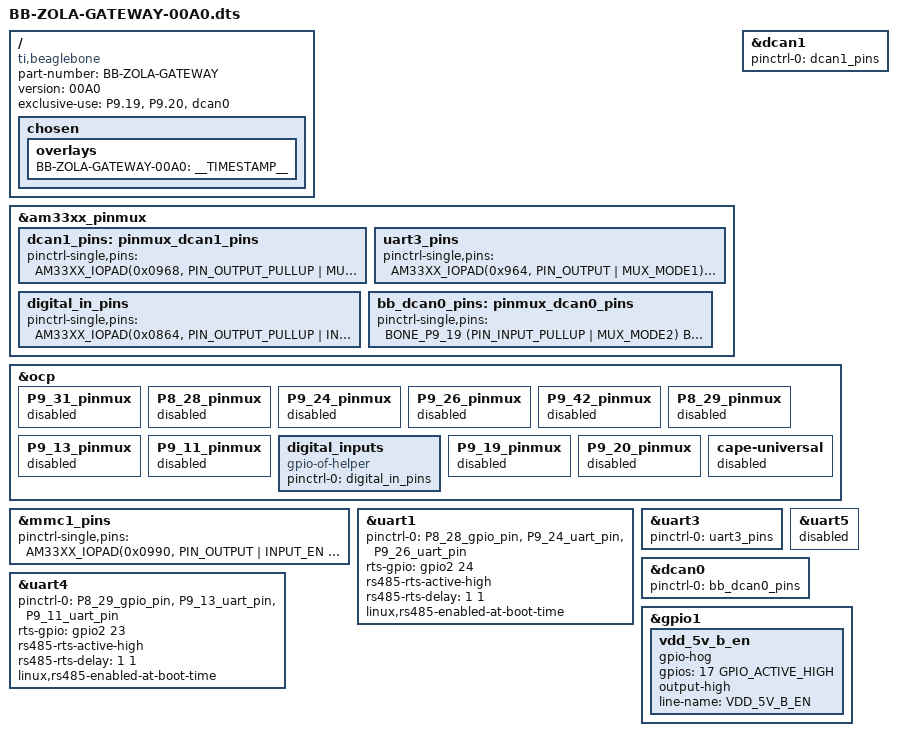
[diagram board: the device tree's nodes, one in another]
/*
 * Copyright (c) 2021 Seeed Studio
 *                    Peter Yang <turmary@126.com>
 *
 * Virtual cape for Zola Gateway
 *
 * This program is free software; you can redistribute it and/or modify
 * it under the terms of the GNU General Public License version 2 as
 * published by the Free Software Foundation.
 */
/dts-v1/;
/plugin/;

#include <dt-bindings/gpio/gpio.h>
#include <dt-bindings/board/am335x-bbw-bbb-base.h>
#include <dt-bindings/pinctrl/am33xx.h>

/ {
	compatible = "ti,beaglebone", "ti,beaglebone-black", "ti,beaglebone-green";

	/* identification */
	part-number = "BB-ZOLA-GATEWAY";
	version = "00A0";

	/* state the resources this cape uses */
	exclusive-use =
		/* the pin header uses */
		"P9.19",	/* dcan0_rx */
		"P9.20",	/* dcan0_tx */
		/* the hardware ip uses */
		"dcan0";

	/*
	 * Helper to show loaded overlays under: /proc/device-tree/chosen/overlays/
	 */
	fragment@1000 {
		target-path="/";
		__overlay__ {

			chosen {
				overlays {
					BB-ZOLA-GATEWAY-00A0 =__TIMESTAMP__;
				};
			};
		};
	};

	/*
	 * Free up the pins used by the cape from the pinmux helpers.
	 */
	fragment@1001 {
		target = <&ocp>;
		__overlay__ {
			P9_19_pinmux { status = "disabled"; };	/* P9_19: i2c2_scl.d_can0_rx */
			P9_20_pinmux { status = "disabled"; };	/* P9_20: i2c2_sda.d_can0_tx */

			/*
			 * Free up the gpios used by the cape-universal gpio helpers.
			 */
			cape-universal { status = "disabled"; };
		};
	};

	fragment@1002 {
		target = <&am33xx_pinmux>;
		__overlay__ {
			bb_dcan0_pins: pinmux_dcan0_pins {
				pinctrl-single,pins = <
					BONE_P9_19 (PIN_INPUT_PULLUP | MUX_MODE2)	/* P9_19: i2c2_scl.d_can0_rx */
					BONE_P9_20 (PIN_OUTPUT_PULLUP | MUX_MODE2)	/* P9_20: i2c2_sda.d_can0_tx */
				>;
			};
		};
	};

	fragment@1003 {
		target = <&dcan0>;
		__overlay__ {
			status = "okay";
			pinctrl-names = "default";
			pinctrl-0 = <&bb_dcan0_pins>;
		};
	};

	fragment@1010 {
		target = <&gpio1>;
		__overlay__ {
			vdd_5v_b_en {
				gpio-hog;
				gpios = <17 GPIO_ACTIVE_HIGH>;
				output-high;
				line-name = "VDD_5V_B_EN";
			};
		};
	};
};

/* DCAN1 */
&am33xx_pinmux {
	dcan1_pins: pinmux_dcan1_pins {
		pinctrl-single,pins = <
			AM33XX_IOPAD(0x0968, PIN_OUTPUT_PULLUP | MUX_MODE2)  /* uart0_ctsn.dcan1_tx */
			AM33XX_IOPAD(0x096c, PIN_INPUT_PULLUP | MUX_MODE2)   /* uart0_rtsn.dcan1_rx */
		>;
	};
};
&dcan1 {
	status = "okay";
	pinctrl-names = "default";
	pinctrl-0 = <&dcan1_pins>;
};

/* MMC1(SDCard) CD gpio0_6 -> gpio3_14 */
&ocp {
	P9_31_pinmux { status = "disabled"; };	/* P9_31: mcasp0_aclkx.gpio3_14 */
};
&mmc1_pins {
	pinctrl-single,pins = <
		AM33XX_IOPAD(0x0990, PIN_OUTPUT | INPUT_EN | MUX_MODE7)  /* mcasp0_aclkx.gpio3_14 */
		AM33XX_PADCONF(AM335X_PIN_MMC0_DAT0, PIN_INPUT_PULLUP, MUX_MODE0)
		AM33XX_PADCONF(AM335X_PIN_MMC0_DAT1, PIN_INPUT_PULLUP, MUX_MODE0)
		AM33XX_PADCONF(AM335X_PIN_MMC0_DAT2, PIN_INPUT_PULLUP, MUX_MODE0)
		AM33XX_PADCONF(AM335X_PIN_MMC0_DAT3, PIN_INPUT_PULLUP, MUX_MODE0)
		AM33XX_PADCONF(AM335X_PIN_MMC0_CMD, PIN_INPUT_PULLUP, MUX_MODE0)
		AM33XX_PADCONF(AM335X_PIN_MMC0_CLK, PIN_INPUT_PULLUP, MUX_MODE0)
	>;
};

/* RS485_1(UART1) on J6 */
&ocp {
	P8_28_pinmux { status = "disabled"; };	/* P8_28: lcd_pclk.gpio2_24 */
	P9_24_pinmux { status = "disabled"; };	/* P9_24: uart1_txd.uart1_txd */
	P9_26_pinmux { status = "disabled"; };	/* P9_26: uart1_rxd.uart1_rxd */
};
&uart1 {
	status = "okay";
	pinctrl-names = "default";
	pinctrl-0 = <&P8_28_gpio_pin &P9_24_uart_pin &P9_26_uart_pin>;
	rts-gpio = <&gpio2 24 GPIO_ACTIVE_HIGH>;
	rs485-rts-active-high;
	/* rs485-rx-during-tx; */
	rs485-rts-delay = <1 1>;
	linux,rs485-enabled-at-boot-time;
};

/* UART3 */
&ocp {
	P9_42_pinmux { status = "disabled"; };	/* P9_42: eCAP0_in_PWM0_out.uart3_txd */
};
&am33xx_pinmux {
	uart3_pins: uart3_pins {
		pinctrl-single,pins = <
			AM33XX_IOPAD(0x964, PIN_OUTPUT | MUX_MODE1) /* ecap0_in_pwm0_out.uart3_txd */
			AM33XX_IOPAD(0x960, PIN_INPUT | MUX_MODE1)  /* spi0_cs1.uart3_rxd */
		>;
	};
};
&uart3 {
	status = "okay";
	pinctrl-names = "default";
	pinctrl-0 = <&uart3_pins>;
};

/* RS485_2(UART4) on J4 */
&ocp {
	P8_29_pinmux { status = "disabled"; };	/* P8_29: lcd_hsync.gpio2_23 */
	P9_13_pinmux { status = "disabled"; };	/* P9_13: gpmc_wpn.uart4_txd */
	P9_11_pinmux { status = "disabled"; };	/* P9_11: gpmc_wait0.uart4_rxd */
};
&uart4 {
	status = "okay";
	pinctrl-names = "default";
	pinctrl-0 = <&P8_29_gpio_pin &P9_13_uart_pin &P9_11_uart_pin>;
	rts-gpio = <&gpio2 23 GPIO_ACTIVE_HIGH>;
	rs485-rts-active-high;
	/* rs485-rx-during-tx; */
	rs485-rts-delay = <1 1>;
	linux,rs485-enabled-at-boot-time;
};

/* UART5 not used */
&uart5 {
	status = "disabled";
};

/* 2x 12V Digital Inputs */
&am33xx_pinmux {
	digital_in_pins: digital_in_pins {
		pinctrl-single,pins = <
			AM33XX_IOPAD(0x0864, PIN_OUTPUT_PULLUP | INPUT_EN | MUX_MODE7)  /* gpmc_a9.gpio1_25 */
			AM33XX_IOPAD(0x086c, PIN_OUTPUT_PULLUP | INPUT_EN | MUX_MODE7)  /* gpmc_a11.gpio1_27 */
		>;
	};
};
&ocp {
	digital_inputs {
		compatible = "gpio-of-helper";
		status = "okay";
		pinctrl-names = "default";
		pinctrl-0 = <&digital_in_pins>;
	};
};

